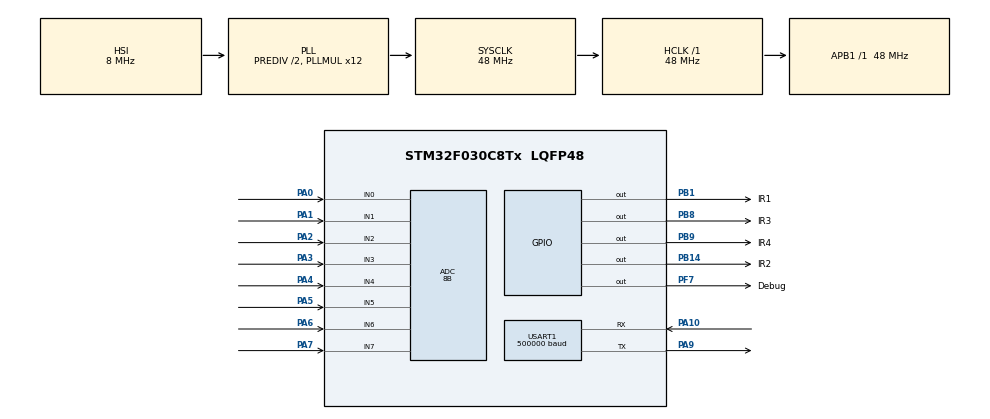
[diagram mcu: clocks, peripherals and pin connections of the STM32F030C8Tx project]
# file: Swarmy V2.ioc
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ADC.ContinuousConvMode=DISABLE
ADC.DMAContinuousRequests=ENABLE
ADC.EOCSelection=ADC_EOC_SINGLE_CONV
ADC.EnableAnalogWatchDog=false
ADC.ExternalTrigConv=ADC_EXTERNALTRIGCONV_T1_TRGO
ADC.Overrun=ADC_OVR_DATA_PRESERVED
ADC.Resolution=ADC_RESOLUTION_8B
ADC.SamplingTime=ADC_SAMPLETIME_13CYCLES_5
ADC.ScanConvMode=ADC_SCAN_DIRECTION_FORWARD
CRC.DefaultInitValueUse=DEFAULT_INIT_VALUE_ENABLE
CRC.InputDataFormat=CRC_INPUTDATA_FORMAT_BYTES
Dma.ADC.0.Direction=DMA_PERIPH_TO_MEMORY
Dma.ADC.0.Instance=DMA1_Channel2
Dma.ADC.0.MemDataAlignment=DMA_MDATAALIGN_HALFWORD
Dma.ADC.0.MemInc=DMA_MINC_ENABLE
Dma.ADC.0.Mode=DMA_CIRCULAR
Dma.ADC.0.PeriphDataAlignment=DMA_PDATAALIGN_HALFWORD
Dma.ADC.0.PeriphInc=DMA_PINC_DISABLE
Dma.ADC.0.Priority=DMA_PRIORITY_LOW
Dma.Request0=ADC
Dma.Request1=USART1_RX
Dma.Request2=USART1_TX
Dma.USART1_RX.1.Direction=DMA_PERIPH_TO_MEMORY
Dma.USART1_RX.1.Instance=DMA1_Channel3
Dma.USART1_RX.1.MemDataAlignment=DMA_MDATAALIGN_BYTE
Dma.USART1_RX.1.MemInc=DMA_MINC_ENABLE
Dma.USART1_RX.1.Mode=DMA_NORMAL
Dma.USART1_RX.1.PeriphDataAlignment=DMA_PDATAALIGN_BYTE
Dma.USART1_RX.1.PeriphInc=DMA_PINC_DISABLE
Dma.USART1_RX.1.Priority=DMA_PRIORITY_LOW
Dma.USART1_TX.2.Direction=DMA_MEMORY_TO_PERIPH
Dma.USART1_TX.2.Instance=DMA1_Channel4
Dma.USART1_TX.2.MemDataAlignment=DMA_MDATAALIGN_BYTE
Dma.USART1_TX.2.MemInc=DMA_MINC_ENABLE
Dma.USART1_TX.2.Mode=DMA_NORMAL
Dma.USART1_TX.2.PeriphDataAlignment=DMA_PDATAALIGN_BYTE
Dma.USART1_TX.2.PeriphInc=DMA_PINC_DISABLE
Dma.USART1_TX.2.Priority=DMA_PRIORITY_LOW
Mcu.Family=STM32F0
Mcu.Name=STM32F030C8Tx
Mcu.Package=LQFP48
NVIC.DMA1_Channel2_3_IRQn=true\:0\:0\:false\:false\:true\:false\:true\:true
NVIC.DMA1_Channel4_5_IRQn=true\:0\:0\:false\:false\:true\:false\:true\:true
NVIC.TIM1_BRK_UP_TRG_COM_IRQn=true\:0\:0\:false\:false\:true\:true\:true\:true
NVIC.TIM3_IRQn=true\:0\:0\:false\:false\:true\:true\:true\:true
NVIC.USART1_IRQn=true\:0\:0\:false\:false\:true\:true\:true\:true
PA0.Mode=IN0
PA0.Signal=ADC_IN0
PA1.Mode=IN1
PA1.Signal=ADC_IN1
PA10.Mode=Asynchronous
PA10.Signal=USART1_RX
PA13.Mode=Serial_Wire
PA13.Signal=SYS_SWDIO
PA14.Mode=Serial_Wire
PA14.Signal=SYS_SWCLK
PA2.Mode=IN2
PA2.Signal=ADC_IN2
PA3.Mode=IN3
PA3.Signal=ADC_IN3
PA4.Mode=IN4
PA4.Signal=ADC_IN4
PA5.Mode=IN5
PA5.Signal=ADC_IN5
PA6.Mode=IN6
PA6.Signal=ADC_IN6
PA7.Mode=IN7
PA7.Signal=ADC_IN7
PA9.Mode=Asynchronous
PA9.Signal=USART1_TX
PB1.GPIO_Label=IR1
PB1.Signal=GPIO_Output
PB14.GPIO_Label=IR2
PB14.Signal=GPIO_Output
PB8.GPIO_Label=IR3
PB8.Signal=GPIO_Output
PB9.GPIO_Label=IR4
PB9.Signal=GPIO_Output
PF0-OSC_IN.Mode=HSE-External-Oscillator
PF0-OSC_IN.Signal=RCC_OSC_IN
PF1-OSC_OUT.Mode=HSE-External-Oscillator
PF1-OSC_OUT.Signal=RCC_OSC_OUT
PF7.GPIO_Label=Debug
PF7.GPIO_Speed=GPIO_SPEED_FREQ_HIGH
PF7.Signal=GPIO_Output
ProjectManager.HeapSize=0x200
ProjectManager.StackSize=0x400
ProjectManager.TargetToolchain=STM32CubeIDE
RCC.AHBFreq_Value=48000000
RCC.APB1Freq_Value=48000000
RCC.APB1TimFreq_Value=48000000
RCC.HCLKFreq_Value=48000000
RCC.PLLDivider=RCC_PREDIV_DIV2
RCC.PLLMUL=RCC_PLL_MUL12
RCC.SYSCLKFreq_VALUE=48000000
RCC.SYSCLKSource=RCC_SYSCLKSOURCE_PLLCLK
TIM1.Period=50 - 1
TIM1.Prescaler=480 - 1
TIM1.TIM_MasterOutputTrigger=TIM_TRGO_UPDATE
TIM3.Period=50 - 1
TIM3.Prescaler=480-1
USART1.BaudRate=500000
USART1.OverSampling=UART_OVERSAMPLING_16
USART1.VirtualMode-Asynchronous=VM_ASYNC
VP_CRC_VS_CRC.Mode=CRC_Activate
VP_TIM1_VS_ClockSourceINT.Mode=Internal
VP_TIM3_VS_ClockSourceINT.Mode=Internal
board=custom

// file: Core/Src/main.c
/* USER CODE BEGIN Header */
/**
  ******************************************************************************
  * @file           : main.c
  * @brief          : Main program body
  ******************************************************************************
  * @attention
  *
  * Copyright (c) 2025 STMicroelectronics.
  * All rights reserved.
  *
  * This software is licensed under terms that can be found in the LICENSE file
  * in the root directory of this software component.
  * If no LICENSE file comes with this software, it is provided AS-IS.
  *
  ******************************************************************************
  */
/* USER CODE END Header */
#include "main.h"

/* USER CODE BEGIN Includes */
#include "Swarmy.h"
/* USER CODE END Includes */

ADC_HandleTypeDef hadc;
DMA_HandleTypeDef hdma_adc;

CRC_HandleTypeDef hcrc;

TIM_HandleTypeDef htim1;
TIM_HandleTypeDef htim3;

UART_HandleTypeDef huart1;
DMA_HandleTypeDef hdma_usart1_rx;
DMA_HandleTypeDef hdma_usart1_tx;

void SystemClock_Config(void);
static void MX_GPIO_Init(void);
static void MX_DMA_Init(void);
static void MX_ADC_Init(void);
static void MX_USART1_UART_Init(void);
static void MX_TIM1_Init(void);
static void MX_TIM3_Init(void);
static void MX_CRC_Init(void);

int main(void)
{

  /* MCU Configuration--------------------------------------------------------*/

  /* Reset of all peripherals, Initializes the Flash interface and the Systick. */
  HAL_Init();

  /* Configure the system clock */
  SystemClock_Config();

  /* Initialize all configured peripherals */
  MX_GPIO_Init();
  MX_DMA_Init();
  MX_ADC_Init();
  MX_USART1_UART_Init();
  MX_TIM1_Init();
  MX_TIM3_Init();
  MX_CRC_Init();
  /* USER CODE BEGIN 2 */
  Swarmy_Setup();
  /* USER CODE END 2 */

  /* Infinite loop */
  /* USER CODE BEGIN WHILE */
  while (1)
  {
    Swarmy_Loop();
    /* USER CODE END WHILE */

  }
}

void SystemClock_Config(void)
{
  RCC_OscInitTypeDef RCC_OscInitStruct = {0};
  RCC_ClkInitTypeDef RCC_ClkInitStruct = {0};
  RCC_PeriphCLKInitTypeDef PeriphClkInit = {0};

  /** Initializes the RCC Oscillators according to the specified parameters
  * in the RCC_OscInitTypeDef structure.
  */
  RCC_OscInitStruct.OscillatorType = RCC_OSCILLATORTYPE_HSI|RCC_OSCILLATORTYPE_HSI14;
  RCC_OscInitStruct.HSIState = RCC_HSI_ON;
  RCC_OscInitStruct.HSI14State = RCC_HSI14_ON;
  RCC_OscInitStruct.HSICalibrationValue = RCC_HSICALIBRATION_DEFAULT;
  RCC_OscInitStruct.HSI14CalibrationValue = 16;
  RCC_OscInitStruct.PLL.PLLState = RCC_PLL_ON;
  RCC_OscInitStruct.PLL.PLLSource = RCC_PLLSOURCE_HSI;
  RCC_OscInitStruct.PLL.PLLMUL = RCC_PLL_MUL12;
  RCC_OscInitStruct.PLL.PREDIV = RCC_PREDIV_DIV2;
  if (HAL_RCC_OscConfig(&RCC_OscInitStruct) != HAL_OK)
  {
    Error_Handler();
  }

  /** Initializes the CPU, AHB and APB buses clocks
  */
  RCC_ClkInitStruct.ClockType = RCC_CLOCKTYPE_HCLK|RCC_CLOCKTYPE_SYSCLK
                              |RCC_CLOCKTYPE_PCLK1;
  RCC_ClkInitStruct.SYSCLKSource = RCC_SYSCLKSOURCE_PLLCLK;
  RCC_ClkInitStruct.AHBCLKDivider = RCC_SYSCLK_DIV1;
  RCC_ClkInitStruct.APB1CLKDivider = RCC_HCLK_DIV1;

  if (HAL_RCC_ClockConfig(&RCC_ClkInitStruct, FLASH_LATENCY_1) != HAL_OK)
  {
    Error_Handler();
  }
  PeriphClkInit.PeriphClockSelection = RCC_PERIPHCLK_USART1;
  PeriphClkInit.Usart1ClockSelection = RCC_USART1CLKSOURCE_PCLK1;
  if (HAL_RCCEx_PeriphCLKConfig(&PeriphClkInit) != HAL_OK)
  {
    Error_Handler();
  }
}

static void MX_ADC_Init(void)
{

  ADC_ChannelConfTypeDef sConfig = {0};

  /** Configure the global features of the ADC (Clock, Resolution, Data Alignment and number of conversion)
  */
  hadc.Instance = ADC1;
  hadc.Init.ClockPrescaler = ADC_CLOCK_ASYNC_DIV1;
  hadc.Init.Resolution = ADC_RESOLUTION_8B;
  hadc.Init.DataAlign = ADC_DATAALIGN_RIGHT;
  hadc.Init.ScanConvMode = ADC_SCAN_DIRECTION_FORWARD;
  hadc.Init.EOCSelection = ADC_EOC_SINGLE_CONV;
  hadc.Init.LowPowerAutoWait = DISABLE;
  hadc.Init.LowPowerAutoPowerOff = DISABLE;
  hadc.Init.ContinuousConvMode = DISABLE;
  hadc.Init.DiscontinuousConvMode = DISABLE;
  hadc.Init.ExternalTrigConv = ADC_EXTERNALTRIGCONV_T1_TRGO;
  hadc.Init.ExternalTrigConvEdge = ADC_EXTERNALTRIGCONVEDGE_RISING;
  hadc.Init.DMAContinuousRequests = ENABLE;
  hadc.Init.Overrun = ADC_OVR_DATA_PRESERVED;
  if (HAL_ADC_Init(&hadc) != HAL_OK)
  {
    Error_Handler();
  }

  /** Configure for the selected ADC regular channel to be converted.
  */
  sConfig.Channel = ADC_CHANNEL_0;
  sConfig.Rank = ADC_RANK_CHANNEL_NUMBER;
  sConfig.SamplingTime = ADC_SAMPLETIME_13CYCLES_5;
  if (HAL_ADC_ConfigChannel(&hadc, &sConfig) != HAL_OK)
  {
    Error_Handler();
  }

  /** Configure for the selected ADC regular channel to be converted.
  */
  sConfig.Channel = ADC_CHANNEL_1;
  if (HAL_ADC_ConfigChannel(&hadc, &sConfig) != HAL_OK)
  {
    Error_Handler();
  }

  /** Configure for the selected ADC regular channel to be converted.
  */
  sConfig.Channel = ADC_CHANNEL_2;
  if (HAL_ADC_ConfigChannel(&hadc, &sConfig) != HAL_OK)
  {
    Error_Handler();
  }

  /** Configure for the selected ADC regular channel to be converted.
  */
  sConfig.Channel = ADC_CHANNEL_3;
  if (HAL_ADC_ConfigChannel(&hadc, &sConfig) != HAL_OK)
  {
    Error_Handler();
  }

  /** Configure for the selected ADC regular channel to be converted.
  */
  sConfig.Channel = ADC_CHANNEL_4;
  if (HAL_ADC_ConfigChannel(&hadc, &sConfig) != HAL_OK)
  {
    Error_Handler();
  }

  /** Configure for the selected ADC regular channel to be converted.
  */
  sConfig.Channel = ADC_CHANNEL_5;
  if (HAL_ADC_ConfigChannel(&hadc, &sConfig) != HAL_OK)
  {
    Error_Handler();
  }

  /** Configure for the selected ADC regular channel to be converted.
  */
  sConfig.Channel = ADC_CHANNEL_6;
  if (HAL_ADC_ConfigChannel(&hadc, &sConfig) != HAL_OK)
  {
    Error_Handler();
  }

  /** Configure for the selected ADC regular channel to be converted.
  */
  sConfig.Channel = ADC_CHANNEL_7;
  if (HAL_ADC_ConfigChannel(&hadc, &sConfig) != HAL_OK)
  {
    Error_Handler();
  }

}

static void MX_CRC_Init(void)
{

  hcrc.Instance = CRC;
  hcrc.Init.DefaultInitValueUse = DEFAULT_INIT_VALUE_ENABLE;
  hcrc.Init.InputDataInversionMode = CRC_INPUTDATA_INVERSION_NONE;
  hcrc.Init.OutputDataInversionMode = CRC_OUTPUTDATA_INVERSION_DISABLE;
  hcrc.InputDataFormat = CRC_INPUTDATA_FORMAT_BYTES;
  if (HAL_CRC_Init(&hcrc) != HAL_OK)
  {
    Error_Handler();
  }

}

static void MX_TIM1_Init(void)
{

  TIM_ClockConfigTypeDef sClockSourceConfig = {0};
  TIM_MasterConfigTypeDef sMasterConfig = {0};

  htim1.Instance = TIM1;
  htim1.Init.Prescaler = 480 - 1;
  htim1.Init.CounterMode = TIM_COUNTERMODE_UP;
  htim1.Init.Period = 50 - 1;
  htim1.Init.ClockDivision = TIM_CLOCKDIVISION_DIV1;
  htim1.Init.RepetitionCounter = 0;
  htim1.Init.AutoReloadPreload = TIM_AUTORELOAD_PRELOAD_DISABLE;
  if (HAL_TIM_Base_Init(&htim1) != HAL_OK)
  {
    Error_Handler();
  }
  sClockSourceConfig.ClockSource = TIM_CLOCKSOURCE_INTERNAL;
  if (HAL_TIM_ConfigClockSource(&htim1, &sClockSourceConfig) != HAL_OK)
  {
    Error_Handler();
  }
  sMasterConfig.MasterOutputTrigger = TIM_TRGO_UPDATE;
  sMasterConfig.MasterSlaveMode = TIM_MASTERSLAVEMODE_DISABLE;
  if (HAL_TIMEx_MasterConfigSynchronization(&htim1, &sMasterConfig) != HAL_OK)
  {
    Error_Handler();
  }

}

static void MX_TIM3_Init(void)
{

  TIM_ClockConfigTypeDef sClockSourceConfig = {0};
  TIM_MasterConfigTypeDef sMasterConfig = {0};

  htim3.Instance = TIM3;
  htim3.Init.Prescaler = 480-1;
  htim3.Init.CounterMode = TIM_COUNTERMODE_UP;
  htim3.Init.Period = 50 - 1;
  htim3.Init.ClockDivision = TIM_CLOCKDIVISION_DIV1;
  htim3.Init.AutoReloadPreload = TIM_AUTORELOAD_PRELOAD_DISABLE;
  if (HAL_TIM_Base_Init(&htim3) != HAL_OK)
  {
    Error_Handler();
  }
  sClockSourceConfig.ClockSource = TIM_CLOCKSOURCE_INTERNAL;
  if (HAL_TIM_ConfigClockSource(&htim3, &sClockSourceConfig) != HAL_OK)
  {
    Error_Handler();
  }
  sMasterConfig.MasterOutputTrigger = TIM_TRGO_RESET;
  sMasterConfig.MasterSlaveMode = TIM_MASTERSLAVEMODE_DISABLE;
  if (HAL_TIMEx_MasterConfigSynchronization(&htim3, &sMasterConfig) != HAL_OK)
  {
    Error_Handler();
  }

}

static void MX_USART1_UART_Init(void)
{

  huart1.Instance = USART1;
  huart1.Init.BaudRate = 500000;
  huart1.Init.WordLength = UART_WORDLENGTH_8B;
  huart1.Init.StopBits = UART_STOPBITS_1;
  huart1.Init.Parity = UART_PARITY_NONE;
  huart1.Init.Mode = UART_MODE_TX_RX;
  huart1.Init.HwFlowCtl = UART_HWCONTROL_NONE;
  huart1.Init.OverSampling = UART_OVERSAMPLING_16;
  huart1.Init.OneBitSampling = UART_ONE_BIT_SAMPLE_DISABLE;
  huart1.AdvancedInit.AdvFeatureInit = UART_ADVFEATURE_NO_INIT;
  if (HAL_UART_Init(&huart1) != HAL_OK)
  {
    Error_Handler();
  }

}

static void MX_DMA_Init(void)
{

  /* DMA controller clock enable */
  __HAL_RCC_DMA1_CLK_ENABLE();

  /* DMA interrupt init */
  /* DMA1_Channel2_3_IRQn interrupt configuration */
  HAL_NVIC_SetPriority(DMA1_Channel2_3_IRQn, 0, 0);
  HAL_NVIC_EnableIRQ(DMA1_Channel2_3_IRQn);
  /* DMA1_Channel4_5_IRQn interrupt configuration */
  HAL_NVIC_SetPriority(DMA1_Channel4_5_IRQn, 0, 0);
  HAL_NVIC_EnableIRQ(DMA1_Channel4_5_IRQn);

}

static void MX_GPIO_Init(void)
{
  GPIO_InitTypeDef GPIO_InitStruct = {0};

  /* GPIO Ports Clock Enable */
  __HAL_RCC_GPIOF_CLK_ENABLE();
  __HAL_RCC_GPIOA_CLK_ENABLE();
  __HAL_RCC_GPIOB_CLK_ENABLE();

  /*Configure GPIO pin Output Level */
  HAL_GPIO_WritePin(GPIOB, IR1_Pin|IR2_Pin|IR3_Pin|IR4_Pin, GPIO_PIN_RESET);

  /*Configure GPIO pin Output Level */
  HAL_GPIO_WritePin(Debug_GPIO_Port, Debug_Pin, GPIO_PIN_RESET);

  /*Configure GPIO pins : IR1_Pin IR2_Pin IR3_Pin IR4_Pin */
  GPIO_InitStruct.Pin = IR1_Pin|IR2_Pin|IR3_Pin|IR4_Pin;
  GPIO_InitStruct.Mode = GPIO_MODE_OUTPUT_PP;
  GPIO_InitStruct.Pull = GPIO_NOPULL;
  GPIO_InitStruct.Speed = GPIO_SPEED_FREQ_LOW;
  HAL_GPIO_Init(GPIOB, &GPIO_InitStruct);

  /*Configure GPIO pin : Debug_Pin */
  GPIO_InitStruct.Pin = Debug_Pin;
  GPIO_InitStruct.Mode = GPIO_MODE_OUTPUT_PP;
  GPIO_InitStruct.Pull = GPIO_NOPULL;
  GPIO_InitStruct.Speed = GPIO_SPEED_FREQ_HIGH;
  HAL_GPIO_Init(Debug_GPIO_Port, &GPIO_InitStruct);

}

void Error_Handler(void)
{
  __disable_irq();
  while (1)
  {
  }
}
